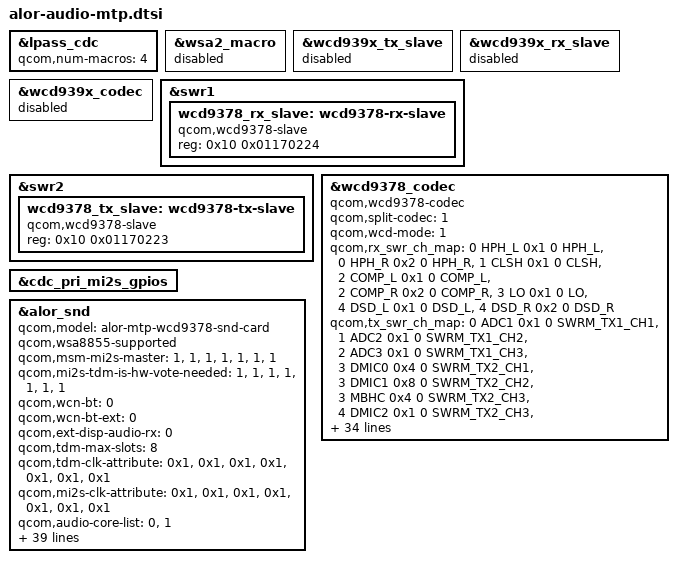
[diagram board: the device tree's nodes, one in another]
//
/* Copyright (c) Qualcomm Technologies, Inc. and/or its subsidiaries.
 *  SPDX-License-Identifier: BSD-3-Clause-Clear
 */

#include "lpass-audio-cdc-1.0.dtsi"
#include "alor-lpi.dtsi"
#include "lpass-audio-bt-swr.dtsi"
#include "lpass-cdc-gpio.dtsi"
#include "alor-audio-lpass-reg.dtsi"
#include "wcd939x.dtsi"
#include "canoe-audio-simple-amp.dtsi"

&lpass_cdc {
	qcom,num-macros = <4>;
};

&wsa2_macro {
	status = "disabled";
};

&wcd939x_tx_slave {
	status = "disabled";
};

&wcd939x_rx_slave {
	status = "disabled";
};

&wcd939x_codec {
	status = "disabled";
	/* 0 for digital crosstalk disabled,
	 * 1 for digital crosstalk with local sensed a-xtalk enabled, and
	 * 2 for digital crosstalk with remote sensed a-xtalk enabled.
	 */
};

/* Below TAMBORA Entries will be moved to wcd939x.dtsi */
&swr1 {
	wcd9378_rx_slave: wcd9378-rx-slave {
		compatible = "qcom,wcd9378-slave";
		reg = <0x10 0x01170224>;
		status = "ok";
	};
};

&swr2 {

	wcd9378_tx_slave: wcd9378-tx-slave {
		status = "ok";
		compatible = "qcom,wcd9378-slave";
		reg = <0x10 0x01170223>;
	};

};
/* This Needs to be uncommented once wcd_usbss node is available */

	/*
	 * &wcd_usbss {
	 * 	status = "diasbled";
	 *};
	 */

&wcd9378_codec {
	status = "ok";
	compatible = "qcom,wcd9378-codec";
	qcom,split-codec = <1>;
	qcom,wcd-mode = <1>;
	qcom,rx_swr_ch_map = <0 HPH_L 0x1 0 HPH_L>,
		<0 HPH_R 0x2 0 HPH_R>, <1 CLSH 0x1 0 CLSH>,
		<2 COMP_L 0x1 0 COMP_L>, <2 COMP_R 0x2 0 COMP_R>,
		<3 LO 0x1 0 LO>, <4 DSD_L 0x1 0 DSD_L>,
		<4 DSD_R 0x2 0 DSD_R>;
	qcom,tx_swr_ch_map = <0 ADC1 0x1 0 SWRM_TX1_CH1>,
		<1 ADC2 0x1 0 SWRM_TX1_CH2>,
		<2 ADC3 0x1 0 SWRM_TX1_CH3>,
		<3 DMIC0 0x4 0 SWRM_TX2_CH1>,
		<3 DMIC1 0x8 0 SWRM_TX2_CH2>,
		<3 MBHC 0x4 0 SWRM_TX2_CH3>,
		<4 DMIC2 0x1 0 SWRM_TX2_CH3>,
		<4 DMIC3 0x2 0 SWRM_TX2_CH4>,
		<4 DMIC4 0x3 0 SWRM_TX3_CH1>,
		<4 DMIC5 0x4 0 SWRM_TX3_CH2>;
	qcom,swr-tx-port-params =
		<OFFSET1_VAL1 LANE0>, <OFFSET1_VAL1 LANE1>,
		<OFFSET1_VAL0 LANE1>, <OFFSET1_VAL1 LANE0>,
		<OFFSET1_VAL0 LANE1>, <OFFSET1_VAL1 LANE0>,
		<OFFSET1_VAL1 LANE0>, <OFFSET1_VAL1 LANE0>,
		<OFFSET1_VAL0 LANE1>, <OFFSET1_VAL2 LANE0>,
		<OFFSET1_VAL1 LANE0>, <OFFSET1_VAL2 LANE0>,
		<OFFSET1_VAL1 LANE0>, <OFFSET1_VAL1 LANE0>,
		<OFFSET1_VAL1 LANE0>, <OFFSET1_VAL1 LANE0>;
	qcom,wcd-rst-gpio-node = <&wcd939x_rst_gpio>;
	qcom,rx-slave = <&wcd9378_rx_slave>;
	qcom,tx-slave = <&wcd9378_tx_slave>;
	cdc-vdd-rxtx-supply = <&L15B>;
	qcom,cdc-vdd-rxtx-voltage = <1800000 1800000>;
	qcom,cdc-vdd-rxtx-current = <30000>;
	qcom,cdc-vdd-rxtx-lpm-supported = <1>;

//	cdc-vdd-io-supply = <&L15B>; //This regulator needs to checked
	qcom,cdc-vdd-io-voltage = <1200000 1200000>;
	qcom,cdc-vdd-io-current = <20000>;
	qcom,cdc-vdd-io-lpm-supported = <1>;

//	cdc-vdd-buck-supply = <&L15B>;
	qcom,cdc-vdd-buck-voltage = <1800000 1800000>;
	qcom,cdc-vdd-buck-current = <650000>;
	qcom,cdc-vdd-buck-lpm-supported = <1>;

	cdc-vdd-mic-bias-supply = <&BOB1>;
	qcom,cdc-vdd-mic-bias-voltage = <3300000 3300000>;
	qcom,cdc-vdd-mic-bias-current = <40055>;

	qcom,cdc-micbias1-mv = <1800>;
	qcom,cdc-micbias2-mv = <1800>;
	qcom,cdc-micbias3-mv = <1800>;
	qcom,cdc-static-supplies = "cdc-vdd-rxtx",
				   "cdc-vdd-io";
	qcom,cdc-on-demand-supplies = "cdc-vdd-buck";

};

&cdc_pri_mi2s_gpios {
	status = "okay";
};

&alor_snd {
	qcom,model = "alor-mtp-wcd9378-snd-card";
	qcom,wsa8855-supported;
	qcom,msm-mi2s-master = <1>, <1>, <1>, <1>, <1>, <1>, <1>;
	qcom,mi2s-tdm-is-hw-vote-needed = <1>, <1>, <1>, <1>, <1>, <1>, <1>;
	qcom,wcn-bt = <0>;
	qcom,wcn-bt-ext = <0>;
	qcom,ext-disp-audio-rx = <0>;
	qcom,tdm-max-slots = <8>;
	qcom,tdm-clk-attribute = <0x1>, <0x1>, <0x1>, <0x1>, <0x1>, <0x1>, <0x1>;
	qcom,mi2s-clk-attribute = <0x1>, <0x1>, <0x1>, <0x1>, <0x1>, <0x1>, <0x1>;
	qcom,audio-core-list = <0>, <1>;
	qcom,msm-mbhc-hs-mic-max-threshold-mv = <1670>;
	qcom,msm-mbhc-usbc-audio-supported = <0>;
	qcom,msm-mbhc-hphl-swh = <1>;
	qcom,msm-mbhc-gnd-swh = <1>;
	asoc-codec  = <&stub_codec>, <&lpass_cdc>,
			<&wcd9378_codec>, <&wsa8855_0230>;
	asoc-codec-names = "msm-stub-codec.1", "lpass-cdc",
			"wcd9378_codec", "sdca-simple-amp.01";
	qcom,audio-routing =
			"AMIC2", "Analog Mic2",
			"AMIC2", "MIC BIAS2",
			"VA AMIC2", "Analog Mic2",
			"VA AMIC2", "VA MIC BIAS2",
			"TX DMIC0", "Digital Mic0",
			"TX DMIC0", "MIC BIAS1",
			"TX DMIC1", "Digital Mic1",
			"TX DMIC1", "MIC BIAS1",
			"TX DMIC2", "Digital Mic2",
			"TX DMIC2", "MIC BIAS3",
			"TX DMIC3", "Digital Mic3",
			"TX DMIC3", "MIC BIAS3",
			"IN1_HPHL", "HPHL_OUT",
			"IN2_HPHR", "HPHR_OUT",
			"IN3_AUX", "AUX_OUT",
			"WSA SRC0_INP", "SRC0",
			"WSA_TX DEC0_INP", "TX DEC0 MUX",
			"WSA_TX DEC1_INP", "TX DEC1 MUX",
			"RX_TX DEC0_INP", "TX DEC0 MUX",
			"RX_TX DEC1_INP", "TX DEC1 MUX",
			"RX_TX DEC2_INP", "TX DEC2 MUX",
			"RX_TX DEC3_INP", "TX DEC3 MUX",
			"SA1 AMP IN", "WSA_SPK1 OUT",
			"SA1 AMP IN", "WSA_SPK2 OUT",
			"VA SWR_INPUT", "VA_SWR_CLK",
			"VA_AIF1 CAP", "VA_SWR_CLK",
			"VA_AIF2 CAP", "VA_SWR_CLK",
			"VA_AIF3 CAP", "VA_SWR_CLK",
			"VA DMIC0", "Digital Mic0",
			"VA DMIC1", "Digital Mic1",
			"VA DMIC2", "Digital Mic2",
			"VA DMIC3", "Digital Mic3",
			"VA DMIC0", "VA MIC BIAS1",
			"VA DMIC1", "VA MIC BIAS1",
			"VA DMIC2", "VA MIC BIAS3",
			"VA DMIC3", "VA MIC BIAS3";
	qcom,wsa-max-devs = <1>;
	/*
	 * Add this property,
	 * To Enable swr haptics through OPCM port.
	 * This will include wsa2 dailinks.
	 */
	qcom,cdc-dmic01-gpios = <&cdc_dmic01_gpios>;
	qcom,cdc-dmic23-gpios = <&cdc_dmic23_gpios>;
	qcom,pri-mi2s-gpios = <&cdc_pri_mi2s_gpios>;
	qcom,msm_audio_ssr_devs = <&audio_gpr>, <&lpi_tlmm>,
				  <&lpass_cdc>, <&lpass_bt_swr>;

		/*
		 * ====================
		 * UPD backend - WSA
		 * ====================
		 *
		 * Mute/Unmute the interpolator
		 * ------------------------------
		 * Register:Â LPASS_WSA_CDC_RX0_RX_PATH_MIX_CTL - 0x6B00418
		 *
		 * Send control commands to the peripheral from the soundwire controller
		 * -----------------------------------------------------------------------
		 * Register: LPASS_WSA_SWR_MSTR_WSA_SWRM_CPUn_CMD_FIFO_WR_CMD - 0x6B14020
		 *
		 * Enable/Disable ear piece
		 * --------------------------
		 * Register:Â DIG_CTRL0_PA_FSM_EN - 0x3430
		 *
		 *
		 *	qcom,upd_backends_used = "wsa";
		 *	qcom,upd_lpass_reg_addr = <0x6B00418 0x6B14020>;
		 *	qcom,upd_ear_pa_reg_addr = <0x3430>;
		 *
		 *
		 * ====================
		 * UPD backend - WCD
		 * ====================
		 *
		 * Mute/Unmute the interpolator
		 * ------------------------------
		 * Register: LPASS_WCD_CDC_RX0_RX_PATH_MIX_CTL - 0x6AC0418
		 *
		 * Send control commands to the wcd from the soundwire controller
		 * ----------------------------------------------------------------
		 * Register: LPASS_WCD_SWR_MSTR_WSA_SWRM_CPUn_CMD_FIFO_WR_CMD - 0x7634020
		 *
		 * Enable/Disable ear piece
		 * --------------------------
		 * Register:Â DIG_CTRL0_PA_FSM_EN - 0x300A
		 *
		 */
	qcom,upd_backends_used = "wcd";
	qcom,upd_lpass_reg_addr = <0x6AC0418 0x7634020>;
	qcom,upd_ear_pa_reg_addr = <0x300A>;
};
